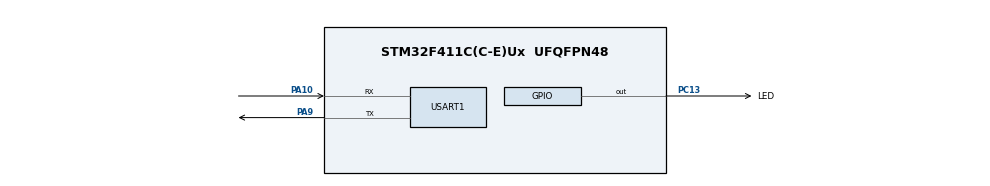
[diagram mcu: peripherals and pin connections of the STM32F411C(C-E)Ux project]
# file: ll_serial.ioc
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Mcu.Family=STM32F4
Mcu.Name=STM32F411C(C-E)Ux
Mcu.Package=UFQFPN48
NVIC.PriorityGroup=NVIC_PRIORITYGROUP_4
PA10.Mode=Asynchronous
PA10.Signal=USART1_RX
PA13.Mode=Serial_Wire
PA13.Signal=SYS_JTMS-SWDIO
PA14.Mode=Serial_Wire
PA14.Signal=SYS_JTCK-SWCLK
PA9.Mode=Asynchronous
PA9.Signal=USART1_TX
PC13-ANTI_TAMP.GPIO_Label=LED
PC13-ANTI_TAMP.GPIO_ModeDefaultOutputPP=GPIO_MODE_OUTPUT_OD
PC13-ANTI_TAMP.PinState=GPIO_PIN_SET
PC13-ANTI_TAMP.Signal=GPIO_Output
PH0\ -\ OSC_IN.Mode=HSE-External-Oscillator
PH0\ -\ OSC_IN.Signal=RCC_OSC_IN
PH1\ -\ OSC_OUT.Mode=HSE-External-Oscillator
PH1\ -\ OSC_OUT.Signal=RCC_OSC_OUT
ProjectManager.HeapSize=0x200
ProjectManager.StackSize=0x400
ProjectManager.TargetToolchain=STM32CubeIDE
RCC.48MHZClocksFreq_Value=48000000
RCC.AHBFreq_Value=96000000
RCC.APB1CLKDivider=RCC_HCLK_DIV2
RCC.APB1Freq_Value=48000000
RCC.APB1TimFreq_Value=96000000
RCC.APB2Freq_Value=96000000
RCC.APB2TimFreq_Value=96000000
RCC.CortexFreq_Value=96000000
RCC.HCLKFreq_Value=96000000
RCC.HSE_VALUE=25000000
RCC.HSI_VALUE=16000000
RCC.LSE_VALUE=32768
RCC.PLLM=25
RCC.PLLSourceVirtual=RCC_PLLSOURCE_HSE
RCC.SYSCLKFreq_VALUE=96000000
RCC.SYSCLKSource=RCC_SYSCLKSOURCE_PLLCLK
RCC.VCOOutputFreq_Value=192000000
USART1.VirtualMode=VM_ASYNC
board=custom

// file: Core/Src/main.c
/* USER CODE BEGIN Header */
/**
 ******************************************************************************
 * @file           : main.c
 * @brief          : Main program body
 ******************************************************************************
 * @attention
 *
 * <h2><center>&copy; Copyright (c) 2021 STMicroelectronics.
 * All rights reserved.</center></h2>
 *
 * This software component is licensed by ST under BSD 3-Clause license,
 * the "License"; You may not use this file except in compliance with the
 * License. You may obtain a copy of the License at:
 *                        opensource.org/licenses/BSD-3-Clause
 *
 ******************************************************************************
 */
/* USER CODE END Header */
#include "main.h"

/* USER CODE BEGIN Includes */
#include "stm32f4xx_it.h"
#include "stdio.h"
/* USER CODE END Includes */

void SystemClock_Config(void);
static void MX_GPIO_Init(void);
static void MX_USART1_UART_Init(void);

/* USER CODE BEGIN 0 */

// Send printf to uart1
int _write(int fd, char *ptr, int len) {
	//const uint8_t *b = ptr;
	while (len--) {
		LL_USART_TransmitData8(USART1, (uint8_t)*ptr++);
		while (!LL_USART_IsActiveFlag_TXE(USART1)) {}
	}
	return len;
}

/* USER CODE END 0 */

int main(void)
{

  /* MCU Configuration--------------------------------------------------------*/

  /* Reset of all peripherals, Initializes the Flash interface and the Systick. */

  LL_APB2_GRP1_EnableClock(LL_APB2_GRP1_PERIPH_SYSCFG);
  LL_APB1_GRP1_EnableClock(LL_APB1_GRP1_PERIPH_PWR);

  NVIC_SetPriorityGrouping(NVIC_PRIORITYGROUP_4);

  /* System interrupt init*/
  /* SysTick_IRQn interrupt configuration */
  NVIC_SetPriority(SysTick_IRQn, NVIC_EncodePriority(NVIC_GetPriorityGrouping(),15, 0));

  /* Configure the system clock */
  SystemClock_Config();

  /* Initialize all configured peripherals */
  MX_GPIO_Init();
  MX_USART1_UART_Init();
  /* USER CODE BEGIN 2 */

	// By default LL SysTick interrupt is not enabled - let's enable it
	LL_SYSTICK_EnableIT();

	DBG("Starting");

  /* USER CODE END 2 */

  /* Infinite loop */
  /* USER CODE BEGIN WHILE */

	uint32_t now = 0, then = 0;

	while (1) {

		now = get_systick_counter();
		if (now - then >= 1000) {
			DBG("Tick %lu", now / 1000);
			then = now;
		}

    /* USER CODE END WHILE */

	}
}

void SystemClock_Config(void)
{
  LL_FLASH_SetLatency(LL_FLASH_LATENCY_3);
  while(LL_FLASH_GetLatency()!= LL_FLASH_LATENCY_3)
  {
  }
  LL_PWR_SetRegulVoltageScaling(LL_PWR_REGU_VOLTAGE_SCALE1);
  LL_RCC_HSE_Enable();

   /* Wait till HSE is ready */
  while(LL_RCC_HSE_IsReady() != 1)
  {

  }
  LL_RCC_PLL_ConfigDomain_SYS(LL_RCC_PLLSOURCE_HSE, LL_RCC_PLLM_DIV_25, 192, LL_RCC_PLLP_DIV_2);
  LL_RCC_PLL_Enable();

   /* Wait till PLL is ready */
  while(LL_RCC_PLL_IsReady() != 1)
  {

  }
  LL_RCC_SetAHBPrescaler(LL_RCC_SYSCLK_DIV_1);
  LL_RCC_SetAPB1Prescaler(LL_RCC_APB1_DIV_2);
  LL_RCC_SetAPB2Prescaler(LL_RCC_APB2_DIV_1);
  LL_RCC_SetSysClkSource(LL_RCC_SYS_CLKSOURCE_PLL);

   /* Wait till System clock is ready */
  while(LL_RCC_GetSysClkSource() != LL_RCC_SYS_CLKSOURCE_STATUS_PLL)
  {

  }
  LL_Init1msTick(96000000);
  LL_SetSystemCoreClock(96000000);
  LL_RCC_SetTIMPrescaler(LL_RCC_TIM_PRESCALER_TWICE);
}

static void MX_USART1_UART_Init(void)
{

  LL_USART_InitTypeDef USART_InitStruct = {0};

  LL_GPIO_InitTypeDef GPIO_InitStruct = {0};

  /* Peripheral clock enable */
  LL_APB2_GRP1_EnableClock(LL_APB2_GRP1_PERIPH_USART1);

  LL_AHB1_GRP1_EnableClock(LL_AHB1_GRP1_PERIPH_GPIOA);
  /**USART1 GPIO Configuration
  PA9   ------> USART1_TX
  PA10   ------> USART1_RX
  */
  GPIO_InitStruct.Pin = LL_GPIO_PIN_9|LL_GPIO_PIN_10;
  GPIO_InitStruct.Mode = LL_GPIO_MODE_ALTERNATE;
  GPIO_InitStruct.Speed = LL_GPIO_SPEED_FREQ_VERY_HIGH;
  GPIO_InitStruct.OutputType = LL_GPIO_OUTPUT_PUSHPULL;
  GPIO_InitStruct.Pull = LL_GPIO_PULL_NO;
  GPIO_InitStruct.Alternate = LL_GPIO_AF_7;
  LL_GPIO_Init(GPIOA, &GPIO_InitStruct);

  USART_InitStruct.BaudRate = 115200;
  USART_InitStruct.DataWidth = LL_USART_DATAWIDTH_8B;
  USART_InitStruct.StopBits = LL_USART_STOPBITS_1;
  USART_InitStruct.Parity = LL_USART_PARITY_NONE;
  USART_InitStruct.TransferDirection = LL_USART_DIRECTION_TX_RX;
  USART_InitStruct.HardwareFlowControl = LL_USART_HWCONTROL_NONE;
  USART_InitStruct.OverSampling = LL_USART_OVERSAMPLING_16;
  LL_USART_Init(USART1, &USART_InitStruct);
  LL_USART_ConfigAsyncMode(USART1);
  LL_USART_Enable(USART1);

}

static void MX_GPIO_Init(void)
{
  LL_GPIO_InitTypeDef GPIO_InitStruct = {0};

  /* GPIO Ports Clock Enable */
  LL_AHB1_GRP1_EnableClock(LL_AHB1_GRP1_PERIPH_GPIOC);
  LL_AHB1_GRP1_EnableClock(LL_AHB1_GRP1_PERIPH_GPIOH);
  LL_AHB1_GRP1_EnableClock(LL_AHB1_GRP1_PERIPH_GPIOA);

  /**/
  LL_GPIO_SetOutputPin(LED_GPIO_Port, LED_Pin);

  /**/
  GPIO_InitStruct.Pin = LED_Pin;
  GPIO_InitStruct.Mode = LL_GPIO_MODE_OUTPUT;
  GPIO_InitStruct.Speed = LL_GPIO_SPEED_FREQ_LOW;
  GPIO_InitStruct.OutputType = LL_GPIO_OUTPUT_OPENDRAIN;
  GPIO_InitStruct.Pull = LL_GPIO_PULL_NO;
  LL_GPIO_Init(LED_GPIO_Port, &GPIO_InitStruct);

}

void Error_Handler(void)
{
	__disable_irq();
	while (1) {
	}
}

/************************ (C) COPYRIGHT STMicroelectronics *****END OF FILE****/
